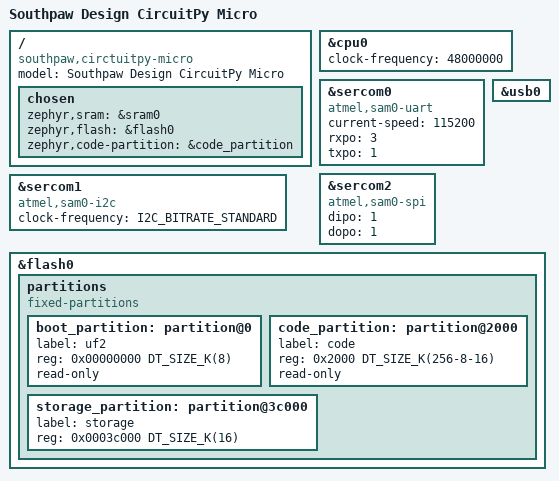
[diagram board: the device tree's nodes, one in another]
/*
 * Copyright (c) 2021 Pete Johanson
 * Copyright (c) 2020 Google LLC.
 *
 * SPDX-License-Identifier: Apache-2.0
 */

/dts-v1/;
#include <atmel/samd21.dtsi>
#include "arduino_pro_micro.dtsi"

/ {
	model = "Southpaw Design CircuitPy Micro";
	compatible = "southpaw,circtuitpy-micro";

	chosen {
		zephyr,sram = &sram0;
		zephyr,flash = &flash0;
		zephyr,code-partition = &code_partition;
	};

};

&cpu0 {
	clock-frequency = <48000000>;
};

&sercom0 {
	compatible = "atmel,sam0-uart";
	current-speed = <115200>;
	rxpo = <3>;
	txpo = <1>;
};

&sercom1 {
	compatible = "atmel,sam0-i2c";
	clock-frequency = <I2C_BITRATE_STANDARD>;
	#address-cells = <1>;
	#size-cells = <0>;
};

&sercom2 {
	compatible = "atmel,sam0-spi";
	dipo = <1>;
	dopo = <1>;
	#address-cells = <1>;
	#size-cells = <0>;
};

&usb0 {
	status = "okay";
};

&flash0 {
	partitions {
		compatible = "fixed-partitions";
		#address-cells = <1>;
		#size-cells = <1>;

		boot_partition: partition@0 {
			label = "uf2";
			reg = <0x00000000 DT_SIZE_K(8)>;
			read-only;
		};

		code_partition: partition@2000 {
			label = "code";
			reg = <0x2000 DT_SIZE_K(256-8-16)>;
			read-only;
		};

		/*
		 * The final 16 KiB is reserved for the application.
		 * Storage partition may be used by FCB or LittleFS.
		 */
		storage_partition: partition@3c000 {
			label = "storage";
			reg = <0x0003c000 DT_SIZE_K(16)>;
		};
	};
};
